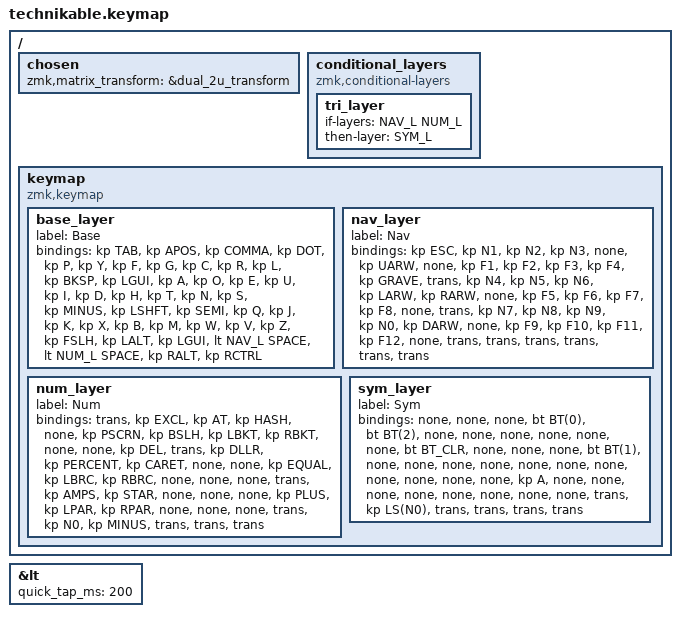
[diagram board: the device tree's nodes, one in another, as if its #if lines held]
/*
 * Copyright (c) 2022 Pete Johanson
 *
 * SPDX-License-Identifier: MIT
 */

#include <behaviors.dtsi>
#include <dt-bindings/zmk/keys.h>
#include <dt-bindings/zmk/bt.h>
#include <dt-bindings/zmk/outputs.h>

#define QWERTY_BASE 1

#define TBLE_ORTHO   true
// #define TBLE_MIT     true
// #define TBLE_DUAL_2U true

#define BAS_L 0
#define NAV_L 1
#define NUM_L 2
#define SYM_L 3

// Using layer taps on thumbs, having quick tap as well helps w/ repeating space/backspace
&lt { quick_tap_ms = <200>; };

#define BT(n) BT_SEL n

/ {
    chosen {
       zmk,matrix_transform =
#ifdef TBLE_DUAL_2U
                       &dual_2u_transform;
#elif defined(TBLE_MIT)
                       &mit_transform;
#else
                       &ortho_transform;
#endif
    };

    conditional_layers {
        compatible = "zmk,conditional-layers";
	tri_layer {
	    if-layers = <NAV_L NUM_L>;
	    then-layer = <SYM_L>;
	};
    };

    keymap {
        compatible = "zmk,keymap";

        base_layer {
            label = "Base";
            bindings = <
#ifdef QWERTY_BASE
 &kp TAB    &kp APOS   &kp COMMA  &kp DOT     &kp P          &kp Y          &kp F            &kp G          &kp C       &kp R      &kp L         &kp BKSP
 &kp LGUI  &kp A      &kp O      &kp E       &kp U          &kp I          &kp D            &kp H          &kp T       &kp N      &kp S         &kp MINUS
 &kp LSHFT  &kp SEMI   &kp Q      &kp J       &kp K          &kp X          &kp B            &kp M          &kp W       &kp V      &kp Z         &kp FSLH
#else
 &kp TAB    &kp Q      &kp W      &kp E       &kp R          &kp T          &kp Y            &kp U          &kp I       &kp O      &kp P        &kp BKSP
 &kp LCTRL  &kp A      &kp S      &kp D       &kp F          &kp G          &kp H            &kp J          &kp K       &kp L      &kp SEMI     &kp QUOT
 &kp LSHFT  &kp Z      &kp X      &kp C       &kp V          &kp B          &kp N            &kp M          &kp COMMA   &kp DOT    &kp FSLH     &kp RET
#endif
#ifdef TBLE_DUAL_2U
                       &kp LALT  &kp LGUI     &lt NAV_L SPACE                &lt NUM_L SPACE              &kp RALT    &kp RCTRL
#elif defined(TBLE_MIT)
                       &kp LCTRL  &kp LALT    &mo NAV_L          &kp SPACE                   &mo NUM_L      &kp RALT    &kp RCTRL
#else
                       &kp LALT   &kp LCTRL    &mo NAV_L      &kp SPACE      &kp RETURN       &mo NUM_L      &kp CAPS    &kp RCTRL
#endif
            >;
        };

        nav_layer {
            label = "Nav";
            bindings = <
&kp ESC    &kp N1     &kp N2    &kp N3      &none       &kp UARW       &none     &kp F1         &kp F2      &kp F3     &kp F4     &kp GRAVE
&trans     &kp N4     &kp N5    &kp N6      &kp LARW    &kp RARW       &none     &kp F5         &kp F6      &kp F7     &kp F8     &none
&trans     &kp N7     &kp N8    &kp N9      &kp N0      &kp DARW       &none     &kp F9         &kp F10     &kp F11    &kp F12    &none
#ifdef TBLE_DUAL_2U
                      &trans     &trans              &trans                    &trans       &trans         &trans
#elif defined(TBLE_MIT)
                      &trans     &trans      &trans                &trans             &trans      &trans   &trans
#else
                      &trans     &trans      &trans          &trans       &trans    &trans     &trans         &trans
#endif
            >;
        };

num_layer {
            label = "Num";
            bindings = <
&trans     &kp EXCL     &kp AT      &kp HASH   &none    &kp PSCRN   &kp BSLH         &kp LBKT    &kp RBKT   &none    &none    &kp DEL
&trans     &kp DLLR     &kp PERCENT &kp CARET  &none    &none       &kp EQUAL        &kp LBRC    &kp RBRC   &none    &none    &none
&trans     &kp AMPS     &kp STAR    &none      &none    &none       &kp PLUS         &kp LPAR    &kp RPAR   &none    &none    &none
#ifdef TBLE_DUAL_2U
                     &trans     &kp N0              &kp MINUS                 &trans            &trans         &trans
#elif defined(TBLE_MIT)
                     &trans     &kp N0      &kp MINUS           &none            &kp ESC        &kp DEL      &trans
#else
                     &trans     &trans      &trans    &trans         &trans      &trans        &trans      &trans
#endif
            >;
        };

        sym_layer {
            label = "Sym";
            bindings = <
&none    &none  	&none 	&bt BT(0)  &bt BT(2)	 &none    	&none    &none    &none       &none       &none     &bt BT_CLR
&none    &none  	&none 	&bt BT(1)  &none 	 &none     	&none    &none    &none       &none       &none     &none
&none    &none  	&none 	&kp A  	   &none  	 &none 	        &none    &none    &none       &none       &none     &none
#ifdef TBLE_DUAL_2U
                      &trans     &kp LS(N0)              &trans                    &trans       &trans         &trans
#elif defined(TBLE_MIT)
                      &trans     &kp LS(N0)      &trans                &trans             &trans      &trans   &trans
#else
                      &none     &none      &trans          &none       &none    &trans  &none         &none
#endif
            >;
        };

    };
};
